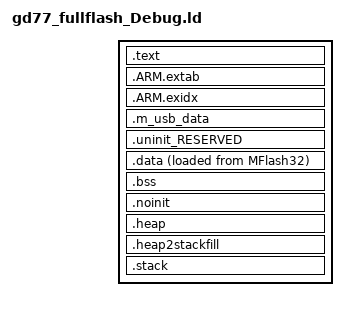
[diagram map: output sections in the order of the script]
/*
 * GENERATED FILE - DO NOT EDIT
 * Copyright (c) 2008 - 2013 Code Red Technologies Ltd, 
 * Copyright 2015, 2018 NXP
 * (c) NXP Semiconductors 2013-2019
 * Generated linker script file for MK22FN512xxx12
 * Created from linkscript.ldt by FMCreateLinkLibraries
 * Using Freemarker v2.3.23
 * MCUXpresso IDE v10.3.1 [Build 2233] [2019-02-20] on 13.03.2019 09:49:42
 */

INCLUDE "../linkerscripts/gd77_fullflash_Debug_library.ld"
INCLUDE "../linkerscripts/gd77_fullflash_Debug_memory.ld"

ResetISR = 0x00000004;  
ENTRY(ResetISR)

SECTIONS
{
    .text :
    {
       . = 0x00000000;
       *(.full_flash*)
        KEEP(*(.full_flash))
    } > MFlash32
    
    /*
     * for exception handling/unwind - some Newlib functions (in common
     * with C++ and STDC++) use this. 
     */
    .ARM.extab : ALIGN(4) 
    {
        *(.ARM.extab* .gnu.linkonce.armextab.*)
    } > MFlash32

    __exidx_start = .;

    .ARM.exidx : ALIGN(4)
    {
        *(.ARM.exidx* .gnu.linkonce.armexidx.*)
    } > MFlash32
    __exidx_end = .;
 
    _etext = .;
        
 
    /* USB_RAM */
    .m_usb_data (NOLOAD) :
    {
        *(m_usb_bdt)
    } > RamLoc8
    /* MAIN DATA SECTION */
    .uninit_RESERVED : ALIGN(4)
    {
        KEEP(*(.bss.$RESERVED*))
        . = ALIGN(4) ;
        _end_uninit_RESERVED = .;
    } > RamLoc8

    /* Main DATA section (RamLoc8) */
    .data : ALIGN(4)
    {
       FILL(0xff)
       _data = . ;
       *(vtable)
       *(.ramfunc*)
       *(.data*)
       . = ALIGN(4) ;
       _edata = . ;
    } > RamLoc8 AT>MFlash32

    /* MAIN BSS SECTION */
    .bss : ALIGN(4)
    {
        _bss = .;
        *(.bss*)
        *(COMMON)
        . = ALIGN(4) ;
        _ebss = .;
        PROVIDE(end = .);
    } > RamLoc8

    /* DEFAULT NOINIT SECTION */
    .noinit (NOLOAD): ALIGN(4)
    {
        _noinit = .;
        *(.noinit*) 
         . = ALIGN(4) ;
        _end_noinit = .;
    } > RamLoc8

    /* Reserve and place Heap within memory map */
    _HeapSize = 0x200;
    .heap :  ALIGN(4)
    {
        _pvHeapStart = .;
        . += _HeapSize;
        . = ALIGN(4);
        _pvHeapLimit = .;
    } > RamLoc8

     _StackSize = 0x200;
     /* Reserve space in memory for Stack */
    .heap2stackfill  :
    {
        . += _StackSize;
    } > RamLoc8
    /* Locate actual Stack in memory map */
    .stack ORIGIN(RamLoc8) + LENGTH(RamLoc8) - _StackSize - 0:  ALIGN(4)
    {
        _vStackBase = .;
        . = ALIGN(4);
        _vStackTop = . + _StackSize;
    } > RamLoc8

    /* Provide basic symbols giving location and size of main text
     * block, including initial values of RW data sections. Note that
     * these will need extending to give a complete picture with
     * complex images (e.g multiple Flash banks).
     */
    _image_start = LOADADDR(.text);
    _image_end = LOADADDR(.data) + SIZEOF(.data);
    _image_size = _image_end - _image_start;
}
